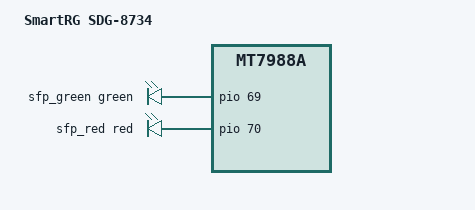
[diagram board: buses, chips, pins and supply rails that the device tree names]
// SPDX-License-Identifier: (GPL-2.0 OR MIT)
/*
 * Copyright (C) 2023 SmartRG Inc.
 * Author: Chad Monroe <chad.monroe@smartrg.com>
 */

#include "mt7988a-smartrg-mt-stuart.dtsi"

/ {
	model = "SmartRG SDG-8734";
	compatible = "smartrg,sdg-8734", "mediatek,mt7988a";
};

&leds {
	sfp_green {
		color = <LED_COLOR_ID_GREEN>;
		function = "sfp";
		gpios = <&pio 69 GPIO_ACTIVE_HIGH>;
	};

	sfp_red {
		color = <LED_COLOR_ID_RED>;
		function = "sfp";
		gpios = <&pio 70 GPIO_ACTIVE_HIGH>;
	};
};

&gmac1 {
	sfp = <&sfp1>;
	managed = "in-band-status";
};
